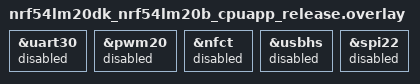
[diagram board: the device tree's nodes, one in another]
/*
 * Copyright (c) 2026 Nordic Semiconductor ASA
 *
 * SPDX-License-Identifier: LicenseRef-Nordic-5-Clause
 */

#include "nrf54lm20dk_nrf54lm20b_cpuapp.overlay"

&uart30 {
	status = "disabled";
};

&pwm20 {
	status = "disabled";
};

&nfct {
	status = "disabled";
};

&usbhs {
	status = "disabled";
};

&spi22 {
	status = "disabled";
};
